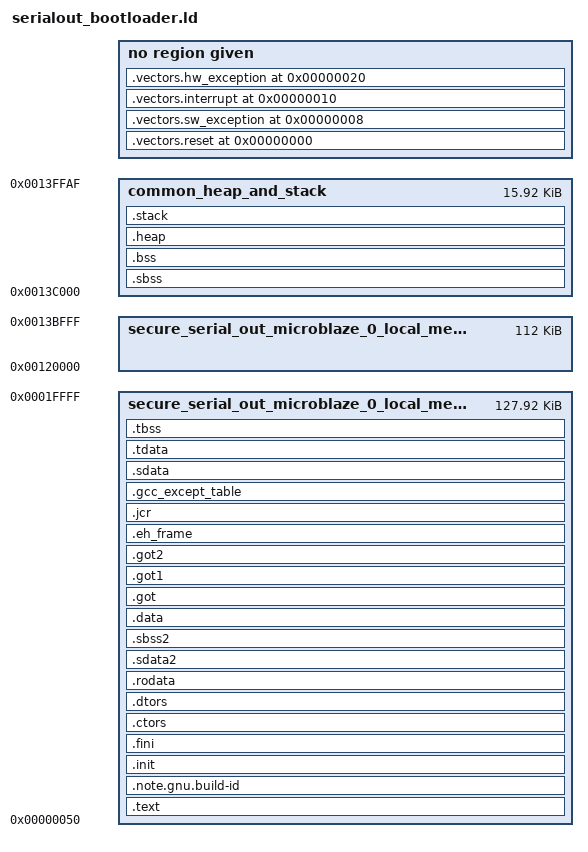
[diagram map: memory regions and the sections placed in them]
/*******************************************************************/
/*                                                                 */
/* This file is automatically generated by linker script generator.*/
/*                                                                 */
/* Version: 2020.1                                                 */
/*                                                                 */
/* Copyright (c) 2010-2019 Xilinx, Inc.  All rights reserved.      */
/*                                                                 */
/* Description : MicroBlaze Linker Script                           */
/*                                                                 */
/*******************************************************************/

_STACK_SIZE = DEFINED(_STACK_SIZE) ? _STACK_SIZE : 0x1000;
_HEAP_SIZE = DEFINED(_HEAP_SIZE) ? _HEAP_SIZE : 0x1000;

/* Define Memories in the system */

MEMORY
{
   secure_serial_out_microblaze_0_local_memory_ilmb_rom_if_ctrlr_Mem_secure_serial_out_microblaze_0_local_memory_dlmb_rom_if_ctrlr_Mem : ORIGIN = 0x50, LENGTH = 0x1FFB0
   secure_serial_out_microblaze_0_local_memory_ilmb_bram_if_cntlr_Mem_secure_serial_out_microblaze_0_local_memory_dlmb_bram_if_cntlr_Mem : ORIGIN = 0x120000, LENGTH = 0x1C000
   common_heap_and_stack : ORIGIN = 0x13C000, LENGTH = 0x3FB0
}

/* Specify the default entry point to the program */

ENTRY(_start)

/* Define the sections, and where they are mapped in memory */

SECTIONS
{
.vectors.reset 0x0 : {
   KEEP (*(.vectors.reset))
} 

.vectors.sw_exception 0x8 : {
   KEEP (*(.vectors.sw_exception))
} 

.vectors.interrupt 0x10 : {
   KEEP (*(.vectors.interrupt))
} 

.vectors.hw_exception 0x20 : {
   KEEP (*(.vectors.hw_exception))
} 

.text : {
   *(.text)
   *(.text.*)
   *(.gnu.linkonce.t.*)
} > secure_serial_out_microblaze_0_local_memory_ilmb_rom_if_ctrlr_Mem_secure_serial_out_microblaze_0_local_memory_dlmb_rom_if_ctrlr_Mem

.note.gnu.build-id : {
   KEEP (*(.note.gnu.build-id))
} > secure_serial_out_microblaze_0_local_memory_ilmb_rom_if_ctrlr_Mem_secure_serial_out_microblaze_0_local_memory_dlmb_rom_if_ctrlr_Mem

.init : {
   KEEP (*(.init))
} > secure_serial_out_microblaze_0_local_memory_ilmb_rom_if_ctrlr_Mem_secure_serial_out_microblaze_0_local_memory_dlmb_rom_if_ctrlr_Mem

.fini : {
   KEEP (*(.fini))
} > secure_serial_out_microblaze_0_local_memory_ilmb_rom_if_ctrlr_Mem_secure_serial_out_microblaze_0_local_memory_dlmb_rom_if_ctrlr_Mem

.ctors : {
   __CTOR_LIST__ = .;
   ___CTORS_LIST___ = .;
   KEEP (*crtbegin.o(.ctors))
   KEEP (*(EXCLUDE_FILE(*crtend.o) .ctors))
   KEEP (*(SORT(.ctors.*)))
   KEEP (*(.ctors))
   __CTOR_END__ = .;
   ___CTORS_END___ = .;
} > secure_serial_out_microblaze_0_local_memory_ilmb_rom_if_ctrlr_Mem_secure_serial_out_microblaze_0_local_memory_dlmb_rom_if_ctrlr_Mem

.dtors : {
   __DTOR_LIST__ = .;
   ___DTORS_LIST___ = .;
   KEEP (*crtbegin.o(.dtors))
   KEEP (*(EXCLUDE_FILE(*crtend.o) .dtors))
   KEEP (*(SORT(.dtors.*)))
   KEEP (*(.dtors))
   PROVIDE(__DTOR_END__ = .);
   PROVIDE(___DTORS_END___ = .);
} > secure_serial_out_microblaze_0_local_memory_ilmb_rom_if_ctrlr_Mem_secure_serial_out_microblaze_0_local_memory_dlmb_rom_if_ctrlr_Mem

.rodata : {
   __rodata_start = .;
   *(.rodata)
   *(.rodata.*)
   *(.gnu.linkonce.r.*)
   __rodata_end = .;
} > secure_serial_out_microblaze_0_local_memory_ilmb_rom_if_ctrlr_Mem_secure_serial_out_microblaze_0_local_memory_dlmb_rom_if_ctrlr_Mem

.sdata2 : {
   . = ALIGN(8);
   __sdata2_start = .;
   *(.sdata2)
   *(.sdata2.*)
   *(.gnu.linkonce.s2.*)
   . = ALIGN(8);
   __sdata2_end = .;
} > secure_serial_out_microblaze_0_local_memory_ilmb_rom_if_ctrlr_Mem_secure_serial_out_microblaze_0_local_memory_dlmb_rom_if_ctrlr_Mem

.sbss2 : {
   __sbss2_start = .;
   *(.sbss2)
   *(.sbss2.*)
   *(.gnu.linkonce.sb2.*)
   __sbss2_end = .;
} > secure_serial_out_microblaze_0_local_memory_ilmb_rom_if_ctrlr_Mem_secure_serial_out_microblaze_0_local_memory_dlmb_rom_if_ctrlr_Mem

.data : {
   . = ALIGN(4);
   __data_start = .;
   *(.data)
   *(.data.*)
   *(.gnu.linkonce.d.*)
   __data_end = .;
} > secure_serial_out_microblaze_0_local_memory_ilmb_rom_if_ctrlr_Mem_secure_serial_out_microblaze_0_local_memory_dlmb_rom_if_ctrlr_Mem

.got : {
   *(.got)
} > secure_serial_out_microblaze_0_local_memory_ilmb_rom_if_ctrlr_Mem_secure_serial_out_microblaze_0_local_memory_dlmb_rom_if_ctrlr_Mem

.got1 : {
   *(.got1)
} > secure_serial_out_microblaze_0_local_memory_ilmb_rom_if_ctrlr_Mem_secure_serial_out_microblaze_0_local_memory_dlmb_rom_if_ctrlr_Mem

.got2 : {
   *(.got2)
} > secure_serial_out_microblaze_0_local_memory_ilmb_rom_if_ctrlr_Mem_secure_serial_out_microblaze_0_local_memory_dlmb_rom_if_ctrlr_Mem

.eh_frame : {
   *(.eh_frame)
} > secure_serial_out_microblaze_0_local_memory_ilmb_rom_if_ctrlr_Mem_secure_serial_out_microblaze_0_local_memory_dlmb_rom_if_ctrlr_Mem

.jcr : {
   *(.jcr)
} > secure_serial_out_microblaze_0_local_memory_ilmb_rom_if_ctrlr_Mem_secure_serial_out_microblaze_0_local_memory_dlmb_rom_if_ctrlr_Mem

.gcc_except_table : {
   *(.gcc_except_table)
} > secure_serial_out_microblaze_0_local_memory_ilmb_rom_if_ctrlr_Mem_secure_serial_out_microblaze_0_local_memory_dlmb_rom_if_ctrlr_Mem

.sdata : {
   . = ALIGN(8);
   __sdata_start = .;
   *(.sdata)
   *(.sdata.*)
   *(.gnu.linkonce.s.*)
   __sdata_end = .;
} > secure_serial_out_microblaze_0_local_memory_ilmb_rom_if_ctrlr_Mem_secure_serial_out_microblaze_0_local_memory_dlmb_rom_if_ctrlr_Mem

.sbss (NOLOAD) : {
   . = ALIGN(4);
   __sbss_start = .;
   *(.sbss)
   *(.sbss.*)
   *(.gnu.linkonce.sb.*)
   . = ALIGN(8);
   __sbss_end = .;
} > common_heap_and_stack

.tdata : {
   __tdata_start = .;
   *(.tdata)
   *(.tdata.*)
   *(.gnu.linkonce.td.*)
   __tdata_end = .;
} > secure_serial_out_microblaze_0_local_memory_ilmb_rom_if_ctrlr_Mem_secure_serial_out_microblaze_0_local_memory_dlmb_rom_if_ctrlr_Mem

.tbss : {
   __tbss_start = .;
   *(.tbss)
   *(.tbss.*)
   *(.gnu.linkonce.tb.*)
   __tbss_end = .;
} > secure_serial_out_microblaze_0_local_memory_ilmb_rom_if_ctrlr_Mem_secure_serial_out_microblaze_0_local_memory_dlmb_rom_if_ctrlr_Mem

.bss (NOLOAD) : {
   . = ALIGN(4);
   __bss_start = .;
   *(.bss)
   *(.bss.*)
   *(.gnu.linkonce.b.*)
   *(COMMON)
   . = ALIGN(4);
   __bss_end = .;
} > common_heap_and_stack

_SDA_BASE_ = __sdata_start + ((__sbss_end - __sdata_start) / 2 );

_SDA2_BASE_ = __sdata2_start + ((__sbss2_end - __sdata2_start) / 2 );

/* Generate Stack and Heap definitions */

.heap (NOLOAD) : {
   . = ALIGN(8);
   _heap = .;
   _heap_start = .;
   . += _HEAP_SIZE;
   _heap_end = .;
} > common_heap_and_stack

.stack (NOLOAD) : {
   _stack_end = .;
   . += _STACK_SIZE;
   . = ALIGN(8);
   _stack = .;
   __stack = _stack;
} > common_heap_and_stack

_end = .;
}


